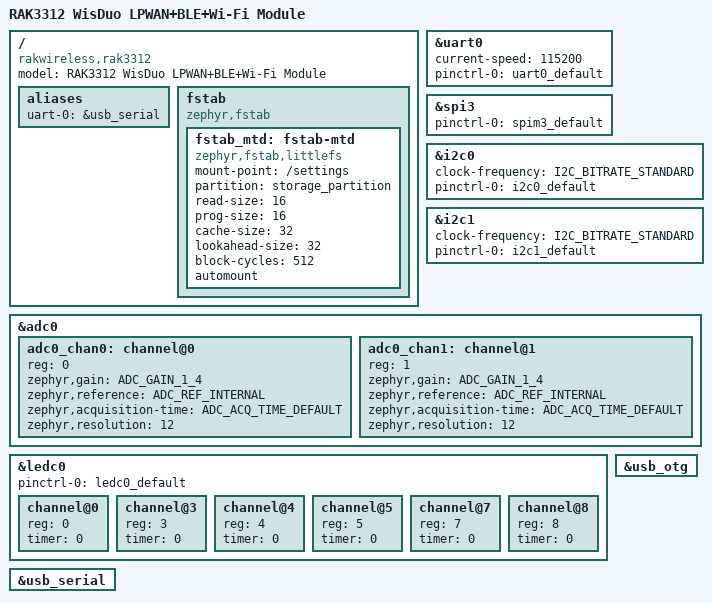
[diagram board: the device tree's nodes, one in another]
/*
 * SPDX-License-Identifier: Apache-2.0
 * Copyright (c) 2026 Shenzhen RAKwireless Technology Co., Ltd.
 */

/dts-v1/;
#include <rakwireless/rak3112_procpu.dtsi>
#include "rak3312-pinctrl.dtsi"

/ {
	model = "RAK3312 WisDuo LPWAN+BLE+Wi-Fi Module";
	compatible = "rakwireless,rak3312";

	aliases {
		uart-0 = &usb_serial;
	};

	fstab {
		compatible = "zephyr,fstab";

		fstab_mtd: fstab-mtd {
			compatible = "zephyr,fstab,littlefs";
			mount-point = "/settings";
			partition = <&storage_partition>;
			read-size = <16>;
			prog-size = <16>;
			cache-size = <32>;
			lookahead-size = <32>;
			block-cycles = <512>;
			automount;
		};
	};
};

&uart0 {
	current-speed = <115200>;
	pinctrl-0 = <&uart0_default>;
	pinctrl-names = "default";
};

&spi3 {
	#address-cells = <1>;
	#size-cells = <0>;
	pinctrl-0 = <&spim3_default>;
	pinctrl-names = "default";
};

&i2c0 {
	clock-frequency = <I2C_BITRATE_STANDARD>;
	pinctrl-0 = <&i2c0_default>;
	pinctrl-names = "default";
};

&i2c1 {
	clock-frequency = <I2C_BITRATE_STANDARD>;
	pinctrl-0 = <&i2c1_default>;
	pinctrl-names = "default";
};

&adc0 {
	status = "okay";
	#address-cells = <1>;
	#size-cells = <0>;

	adc0_chan0: channel@0 {
		reg = <0>;
		zephyr,gain = "ADC_GAIN_1_4";
		zephyr,reference = "ADC_REF_INTERNAL";
		zephyr,acquisition-time = <ADC_ACQ_TIME_DEFAULT>;
		zephyr,resolution = <12>;
	};

	adc0_chan1: channel@1 {
		reg = <1>;
		zephyr,gain = "ADC_GAIN_1_4";
		zephyr,reference = "ADC_REF_INTERNAL";
		zephyr,acquisition-time = <ADC_ACQ_TIME_DEFAULT>;
		zephyr,resolution = <12>;
	};
};


&ledc0 {
	status = "okay";
	pinctrl-0 = <&ledc0_default>;
	pinctrl-names = "default";
	#address-cells = <1>;
	#size-cells = <0>;

	channel@0 {
		reg = <0>;
		timer = <0>;
	};

	channel@3 {
		reg = <3>;
		timer = <0>;
	};

	channel@4 {
		reg = <4>;
		timer = <0>;
	};

	channel@5 {
		reg = <5>;
		timer = <0>;
	};


	channel@7 {
		reg = <7>;
		timer = <0>;
	};

	channel@8 {
		reg = <8>;
		timer = <0>;
	};
};

zephyr_udc0: &usb_otg {};

&usb_serial {
	status = "okay";
};

#include "wisblock.dtsi"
